# STM32F3x8 register map
File version: 1.2
CPU: CM4 r0p0, little endian, 4 interrupt priority bits
Registers are 32-bit, read-write, reset 0x0 unless marked. A register's access mark holds for its fields unless they carry their own. Offsets are from the block's base; [hi:lo] are bit positions; {n}, {i} and the like mark numbered series.

## DAC1 — Digital-to-analog converter
Base 0x40007400
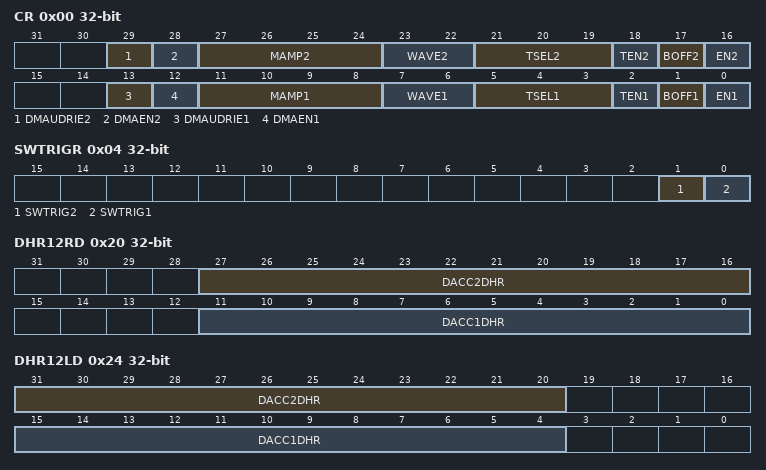
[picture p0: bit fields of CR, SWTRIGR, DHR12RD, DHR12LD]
0x00 CR — control register
  [29] DMAUDRIE2 — DAC channel2 DMA underrun interrupt enable
  [28] DMAEN2 — DAC channel2 DMA enable
  [27:24] MAMP2 — DAC channel2 mask/amplitude selector
  [23:22] WAVE2 — DAC channel2 noise/triangle wave generation enable
  [21:19] TSEL2 — DAC channel2 trigger selection
  [18] TEN2 — DAC channel2 trigger enable
  [17] BOFF2 — DAC channel2 output buffer disable
  [16] EN2 — DAC channel2 enable
  [13] DMAUDRIE1 — DAC channel1 DMA Underrun Interrupt enable
  [12] DMAEN1 — DAC channel1 DMA enable
  [11:8] MAMP1 — DAC channel1 mask/amplitude selector
  [7:6] WAVE1 — DAC channel1 noise/triangle wave generation enable
  [5:3] TSEL1 — DAC channel1 trigger selection
  [2] TEN1 — DAC channel1 trigger enable
  [1] BOFF1 — DAC channel1 output buffer disable
  [0] EN1 — DAC channel1 enable
0x04 SWTRIGR wo — software trigger register
  [1] SWTRIG2 — DAC channel2 software trigger
  [0] SWTRIG1 — DAC channel1 software trigger
0x08 DHR12R1 — channel1 12-bit right-aligned data holding register
  [11:0] DACC1DHR — DAC channel1 12-bit right-aligned data
0x0C DHR12L1 — channel1 12-bit left aligned data holding register
  [15:4] DACC1DHR — DAC channel1 12-bit left-aligned data
0x10 DHR8R1 — channel1 8-bit right aligned data holding register
  [7:0] DACC1DHR — DAC channel1 8-bit right-aligned data
0x14 DHR12R2 — channel2 12-bit right aligned data holding register
  [11:0] DACC2DHR — DAC channel2 12-bit right-aligned data
0x18 DHR12L2 — channel2 12-bit left aligned data holding register
  [15:4] DACC2DHR — DAC channel2 12-bit left-aligned data
0x1C DHR8R2 — channel2 8-bit right-aligned data holding register
  [7:0] DACC2DHR — DAC channel2 8-bit right-aligned data
0x20 DHR12RD — Dual DAC 12-bit right-aligned data holding register
  [27:16] DACC2DHR — DAC channel2 12-bit right-aligned data
  [11:0] DACC1DHR — DAC channel1 12-bit right-aligned data
0x24 DHR12LD — DUAL DAC 12-bit left aligned data holding register
  [31:20] DACC2DHR — DAC channel2 12-bit left-aligned data
  [15:4] DACC1DHR — DAC channel1 12-bit left-aligned data
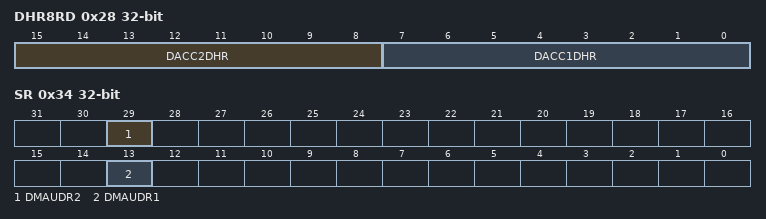
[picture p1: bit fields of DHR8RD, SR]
0x28 DHR8RD — DUAL DAC 8-bit right aligned data holding register
  [15:8] DACC2DHR — DAC channel2 8-bit right-aligned data
  [7:0] DACC1DHR — DAC channel1 8-bit right-aligned data
0x2C DOR1 ro — channel1 data output register
  [11:0] DACC1DOR — DAC channel1 data output
0x30 DOR2 ro — channel2 data output register
  [11:0] DACC2DOR — DAC channel2 data output
0x34 SR — status register
  [29] DMAUDR2 — DAC channel2 DMA underrun flag
  [13] DMAUDR1 — DAC channel1 DMA underrun flag

## NVIC — Nested Vectored Interrupt Controller
Base 0xE000E000
0x04 ICTR ro — Interrupt Controller Type Register
  [3:0] INTLINESNUM — Total number of interrupt lines in groups
{0x100+4i} ISER{i} (i=0..2) — Interrupt Set-Enable Register
  [31:0] SETENA
{0x180+4i} ICER{i} (i=0..2) — Interrupt Clear-Enable Register
  [31:0] CLRENA
{0x200+4i} ISPR{i} (i=0..2) — Interrupt Set-Pending Register
  [31:0] SETPEND
{0x280+4i} ICPR{i} (i=0..2) — Interrupt Clear-Pending Register
  [31:0] CLRPEND
{0x300+4i} IABR{i} ro (i=0..2) — Interrupt Active Bit Register
  [31:0] ACTIVE
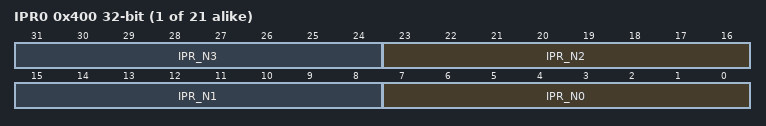
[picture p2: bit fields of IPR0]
{0x400+4i} IPR{i} (i=0..20) — Interrupt Priority Register
  [8n+7:8n] IPR_N{n} (n=0..3)

## FPU — Floting point unit
Base 0xE000EB88
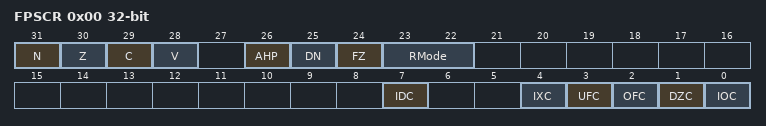
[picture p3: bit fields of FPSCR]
0x00 FPSCR — Floating-point Status and Control Register
  [31] N — Negative condition code flag
  [30] Z — Zero condition code flag
  [29] C — Carry condition code flag
  [28] V — Overflow condition code flag
  [26] AHP — Alternative half-precision control bit
  [25] DN — Default NaN mode control bit
  [24] FZ — Flush-to-zero mode control bit
  [23:22] RMode — Rounding Mode control field.
  [7] IDC — Input Denormal cumulative exception bit
  [4] IXC — Inexact cumulative exception bit
  [3] UFC — Underflow cumulative exception bit
  [2] OFC — Overflow cumulative exception bit
  [1] DZC — Division by Zero cumulative exception bit
  [0] IOC — Invalid Operation cumulative exception bit
